# ML630Q464 register map
Vendor: LAPIS Semiconductor Co.,Ltd.; File version: 1.00
CPU: CM0PLUS r0p1, little endian, no MPU, no FPU, 2 interrupt priority bits
Registers are 32-bit, read-write, no defined reset value unless marked. A register's access mark holds for its fields unless they carry their own. Offsets are from the block's base; [hi:lo] are bit positions; {n}, {i} and the like mark numbered series.

## PORT0
Base 0x5C004000
0x00 P0D
  [5:0] D
0x04 P0DIR
  [5:0] D
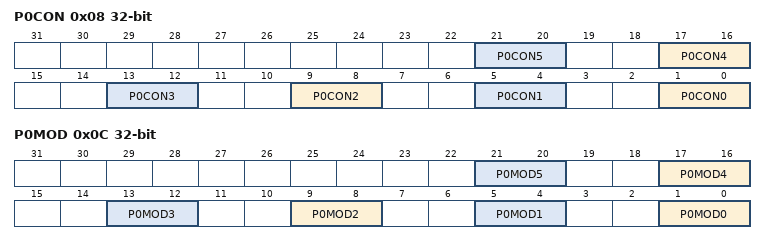
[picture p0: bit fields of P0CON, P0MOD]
0x08 P0CON
  [4n+1:4n] P0CON{n} (n=0..5)
0x0C P0MOD
  [4n+1:4n] P0MOD{n} (n=0..5)

## PORT2
Base 0x5C004200
0x00 P2D
  [3:0] D
0x04 P2DIR
  [3:0] D
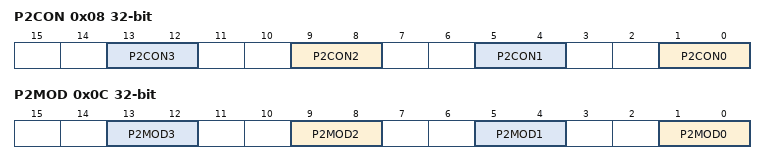
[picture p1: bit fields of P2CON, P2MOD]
0x08 P2CON
  [4n+1:4n] P2CON{n} (n=0..3)
0x0C P2MOD
  [4n+1:4n] P2MOD{n} (n=0..3)

## PORT3
Base 0x5C004300
0x00 P3D
  [7:0] D
0x04 P3DIR
  [7:0] D
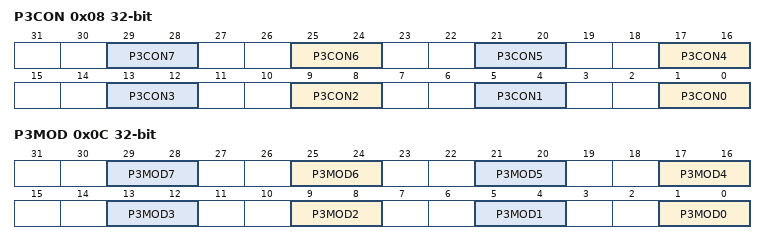
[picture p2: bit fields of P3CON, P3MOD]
0x08 P3CON
  [4n+1:4n] P3CON{n} (n=0..7)
0x0C P3MOD
  [4n+1:4n] P3MOD{n} (n=0..7)

## PORT4
Base 0x5C004400
0x00 P4D
  [7:0] D
0x04 P4DIR
  [7:0] D
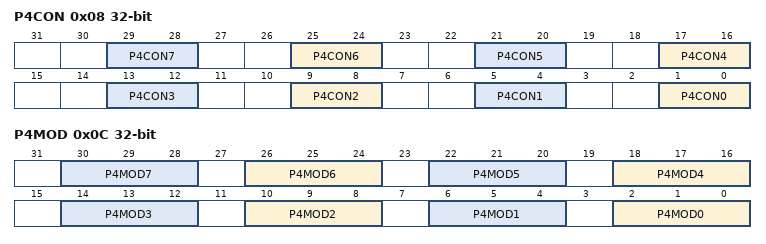
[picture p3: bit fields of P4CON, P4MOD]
0x08 P4CON
  [4n+1:4n] P4CON{n} (n=0..7)
0x0C P4MOD
  [4n+2:4n] P4MOD{n} (n=0..7)

## PORT5
Base 0x5C004500
0x00 P5D
  [7:0] D
0x04 P5DIR
  [7:0] D
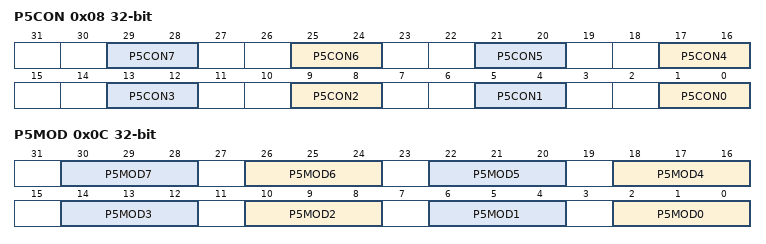
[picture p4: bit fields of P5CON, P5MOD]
0x08 P5CON
  [4n+1:4n] P5CON{n} (n=0..7)
0x0C P5MOD
  [4n+2:4n] P5MOD{n} (n=0..7)

## PORT6
Base 0x5C004600
0x00 P6D
  [3:0] D
0x04 P6DIR
  [3:0] D
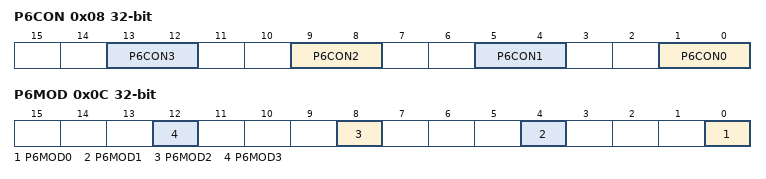
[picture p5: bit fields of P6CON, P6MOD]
0x08 P6CON
  [4n+1:4n] P6CON{n} (n=0..3)
0x0C P6MOD
  [4n] P6MOD{n} (n=0..3)

## RADC
Base 0x42000000
0x00 RADCA
  [23:0] RADCAD
0x04 RADCB
  [23:0] RADCBD
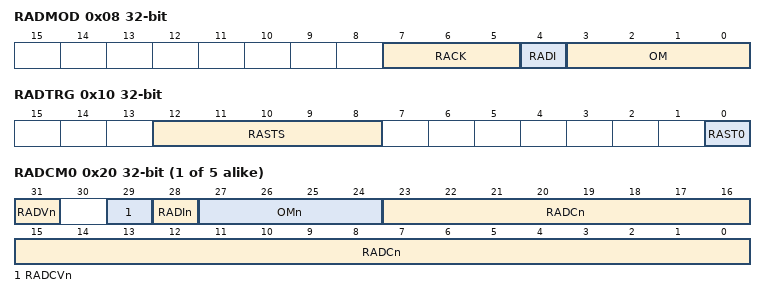
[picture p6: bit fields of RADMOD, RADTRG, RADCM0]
0x08 RADMOD
  [7:5] RACK, [4] RADI, [3:0] OM
0x0C RADCON
  [0] RARUN
0x10 RADTRG
  [12:8] RASTS, [0] RAST0
{0x20+4i} RADCM{i} (i=0..4)
  [31] RADVn, [29] RADCVn, [28] RADIn, [27:24] OMn, [23:0] RADCn
0x40 RADRC
  [23:0] RADCD

## SADC
Base 0x42001000
{0x0+4i} SADR{i} ro (i=0..9)
  [11:0] SARn
0x28 SADRA ro
  [11:0] SARn
0x2C SADRB ro
  [11:0] SARn
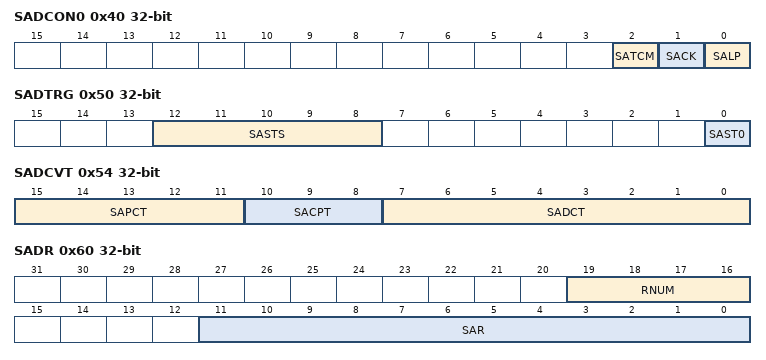
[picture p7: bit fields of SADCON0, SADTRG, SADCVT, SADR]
0x40 SADCON0
  [2] SATCM, [1] SACK, [0] SALP
0x44 SADCON1
  [0] SARUN
0x48 SADEN
  [11:0] SACH
0x4C SADTCH
  [11:0] SATCH
0x50 SADTRG
  [12:8] SASTS, [0] SAST0
0x54 SADCVT
  [15:11] SAPCT, [10:8] SACPT, [7:0] SADCT
0x60 SADR ro
  [19:16] RNUM, [11:0] SAR

## LCDCNT
Base 0x43000000
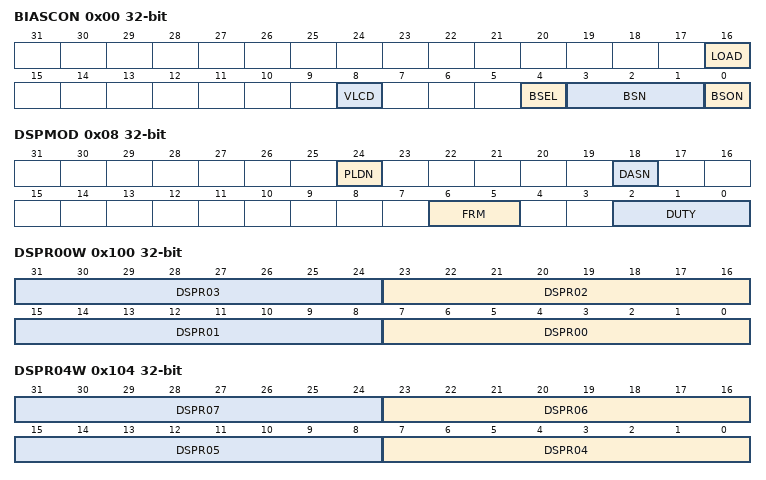
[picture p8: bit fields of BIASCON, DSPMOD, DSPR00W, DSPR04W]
0x00 BIASCON
  [16] LOAD, [8] VLCD, [4] BSEL, [3:1] BSN, [0] BSON
0x04 DSPCNT
  [4:0] LCN
0x08 DSPMOD
  [24] PLDN, [18] DASN, [6:5] FRM, [2:0] DUTY
0x0C DSPCON
  [1:0] LMD
0x100 DSPR00W
  [8n+7:8n] DSPR{n:02} (n=0..3)
0x104 DSPR04W
  [8n-25:8n-32] DSPR{n:02} (n=4..7)
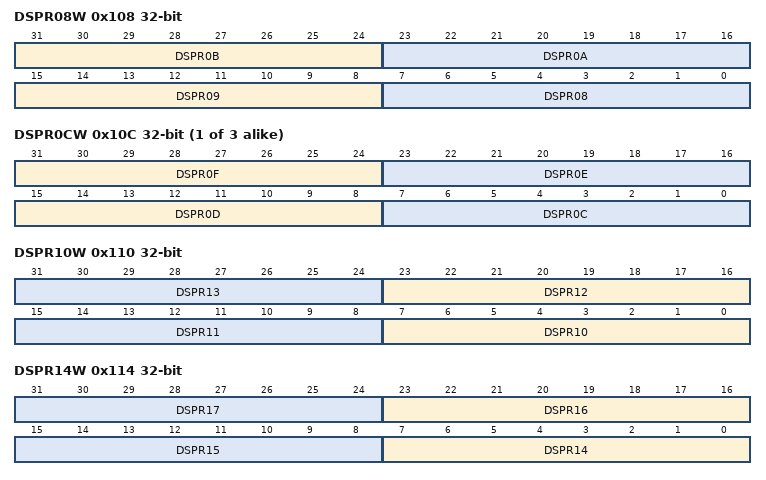
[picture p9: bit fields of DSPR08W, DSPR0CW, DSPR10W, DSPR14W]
0x108 DSPR08W
  [31:24] DSPR0B, [23:16] DSPR0A, [15:8] DSPR09, [7:0] DSPR08
{0x10C+0x10*i} DSPR{i}CW (i=0..2)
  [31:24] DSPR{i}F, [23:16] DSPR{i}E, [15:8] DSPR{i}D, [7:0] DSPR{i}C
0x110 DSPR10W
  [8n-73:8n-80] DSPR{n} (n=10..13)
0x114 DSPR14W
  [8n-105:8n-112] DSPR{n} (n=14..17)
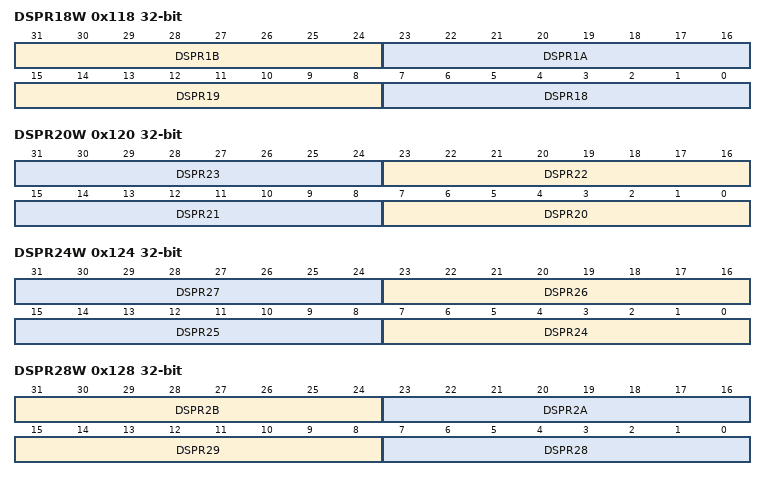
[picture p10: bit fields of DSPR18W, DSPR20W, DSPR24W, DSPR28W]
0x118 DSPR18W
  [31:24] DSPR1B, [23:16] DSPR1A, [15:8] DSPR19, [7:0] DSPR18
0x120 DSPR20W
  [8n-153:8n-160] DSPR{n} (n=20..23)
0x124 DSPR24W
  [8n-185:8n-192] DSPR{n} (n=24..27)
0x128 DSPR28W
  [31:24] DSPR2B, [23:16] DSPR2A, [15:8] DSPR29, [7:0] DSPR28
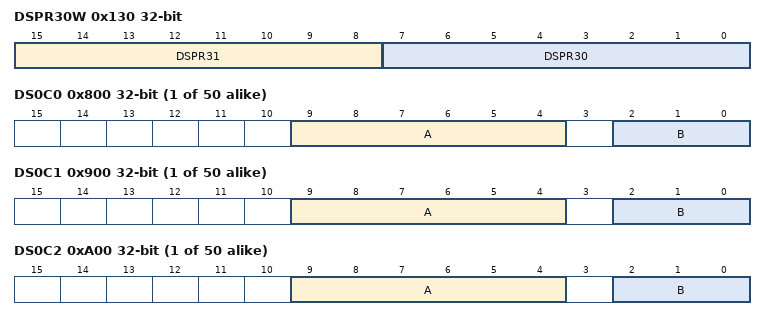
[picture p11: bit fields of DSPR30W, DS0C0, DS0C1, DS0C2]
0x130 DSPR30W
  [15:8] DSPR31, [7:0] DSPR30
{0x800+4i} DS{i}C0 (i=0..49)
  [9:4] A, [2:0] B
{0x900+4i} DS{i}C1 (i=0..49)
  [9:4] A, [2:0] B
{0xA00+4i} DS{i}C2 (i=0..49)
  [9:4] A, [2:0] B
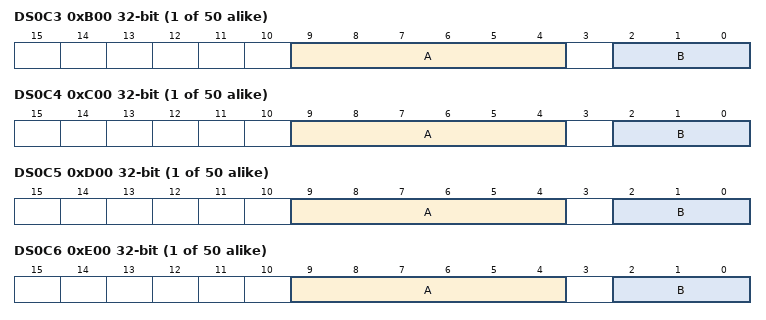
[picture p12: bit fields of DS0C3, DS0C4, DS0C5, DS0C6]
{0xB00+4i} DS{i}C3 (i=0..49)
  [9:4] A, [2:0] B
{0xC00+4i} DS{i}C4 (i=0..49)
  [9:4] A, [2:0] B
{0xD00+4i} DS{i}C5 (i=0..49)
  [9:4] A, [2:0] B
{0xE00+4i} DS{i}C6 (i=0..49)
  [9:4] A, [2:0] B
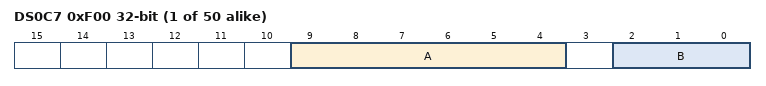
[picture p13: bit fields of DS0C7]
{0xF00+4i} DS{i}C7 (i=0..49)
  [9:4] A, [2:0] B

## CMP
Base 0x5C005100
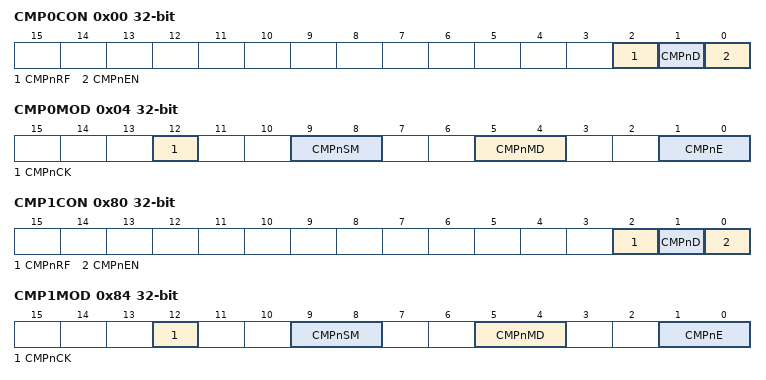
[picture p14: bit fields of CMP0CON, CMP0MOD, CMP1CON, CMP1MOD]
0x00 CMP0CON access per field
  [2] CMPnRF ro, [1] CMPnD ro, [0] CMPnEN rw
0x04 CMP0MOD
  [12] CMPnCK, [9:8] CMPnSM, [5:4] CMPnMD, [1:0] CMPnE
0x80 CMP1CON access per field
  [2] CMPnRF ro, [1] CMPnD ro, [0] CMPnEN rw
0x84 CMP1MOD
  [12] CMPnCK, [9:8] CMPnSM, [5:4] CMPnMD, [1:0] CMPnE
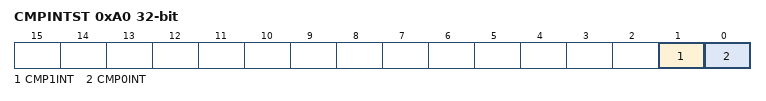
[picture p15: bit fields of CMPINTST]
0xA0 CMPINTST
  [1] CMP1INT, [0] CMP0INT

## VLS
Base 0x5C005000
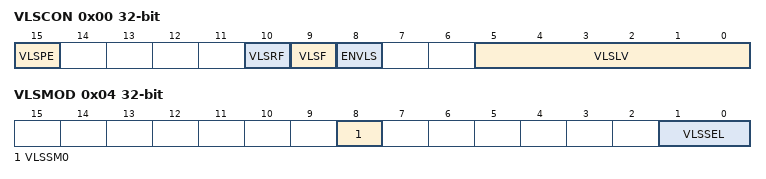
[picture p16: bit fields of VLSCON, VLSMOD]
0x00 VLSCON access per field
  [15] VLSPE rw, [10] VLSRF ro, [9] VLSF ro, [8] ENVLS rw, [5:0] VLSLV rw
0x04 VLSMOD
  [8] VLSSM0, [1:0] VLSSEL

## LSICNT
Base 0x5C000000
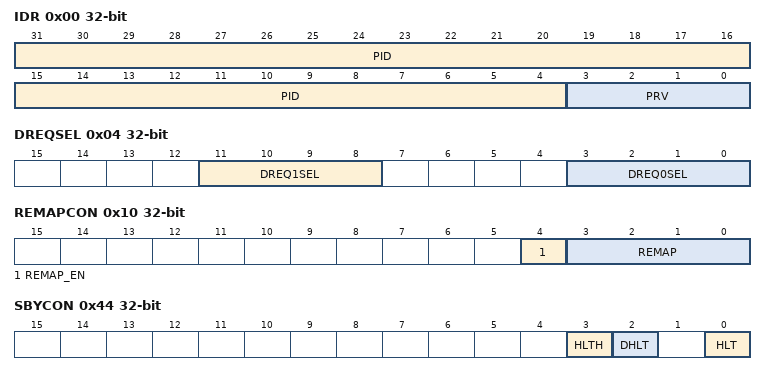
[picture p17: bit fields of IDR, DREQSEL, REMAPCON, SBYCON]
0x00 IDR ro
  [31:4] PID, [3:0] PRV
0x04 DREQSEL
  [11:8] DREQ1SEL, [3:0] DREQ0SEL
0x08 BRMPCON
  [0] PDEN
0x10 REMAPCON
  [4] REMAP_EN, [3:0] REMAP
0x14 REMAPBASE
  [29:12] REMAP_BASE
0x30 TESTREG
  [3:0] MOP
0x44 SBYCON
  [3] HLTH, [2] DHLT, [0] HLT
0x48 PMCON
  [2] LXTHVN, [1] UDHON, [0] UDHEN
0x4C CLKCON
  [31] CCMP1, [30] CCMP0, [29] CDMAC, [27] CVLS, [26] CRTC, [25] CLCD, [24] CUSB, [23] CRND, [22] CAES, [21] CI2CF0, [20] CI2C1, [19] CUAF0, [18] CUA0, [17] CSIOF0, [16] CSIO0, [15] CTM1K, [14] CRAD, [13] CSAD, [n+8] CFTM{n} (n=0..3), [n] CTM{n} (n=0..7)
0x50 RSTCON
  [31] RCMP1, [30] RCMP0, [29] RDMAC, [28] RLLD, [27] RVLS, [26] RRTC, [25] RLCD, [24] RUSB, [23] RRND, [22] RAES, [21] RI2CF0, [20] RI2C1, [19] RUAF0, [18] RUA0, [17] RSIOF0, [16] RSIO0, [15] RTM1K, [14] RRAD, [13] RSAD, [n+8] RFTM{n} (n=0..3), [n] RTM{n} (n=0..7)
